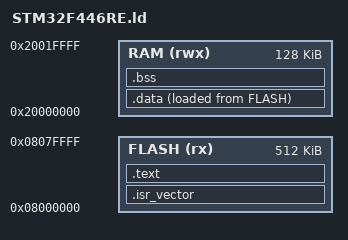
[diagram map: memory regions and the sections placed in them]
/* Minimal GNU linker script for STM32F446RE bare-metal example. */
ENTRY(Reset_Handler)

MEMORY
{
    FLASH (rx)  : ORIGIN = 0x08000000, LENGTH = 512K
    RAM   (rwx) : ORIGIN = 0x20000000, LENGTH = 128K
}
_estack = ORIGIN(RAM) + LENGTH(RAM);

SECTIONS
{
    .isr_vector :
    {
        . = ALIGN(256);
        KEEP(*(.isr_vector))
        . = ALIGN(4);
    } > FLASH
    .text :
    {
        . = ALIGN(4);
        *(.text*)
        *(.rodata*)
        . = ALIGN(4);
        _etext = .;
    } > FLASH
    .data :
    {
        . = ALIGN(4);
        _sdata = .;
        *(.data*)
        . = ALIGN(4);
        _edata = .;
    } > RAM AT > FLASH
    _sidata = LOADADDR(.data);
    .bss (NOLOAD) :
    {
        . = ALIGN(4);
        _sbss = .;
        *(.bss*)
        *(COMMON)
        . = ALIGN(4);
        _ebss = .;
    } > RAM
    /DISCARD/ :
    {
        *(.comment*)
        *(.note.GNU-stack)
    }
}
